VERSION ""

NS_ :

BS_:

BU_: SEND RECV

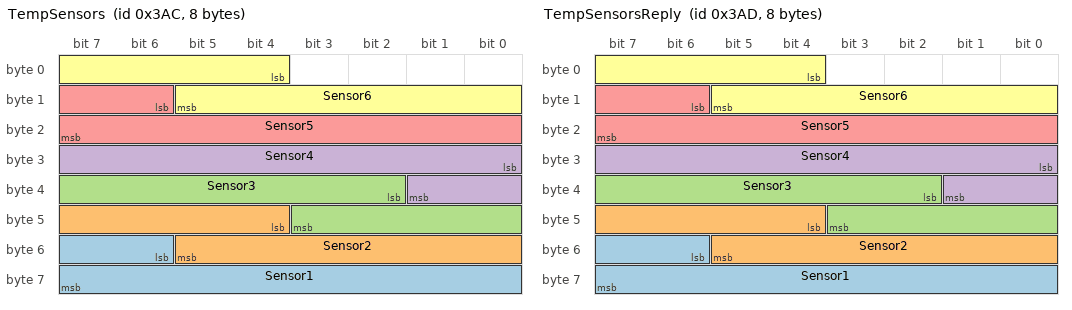
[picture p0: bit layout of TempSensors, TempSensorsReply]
BO_ 940 TempSensors: 8 SEND
    SG_ Sensor1 : 54|10@1- (0.2,0) [0|0] "degC" RECV
    SG_ Sensor2 : 44|10@1- (0.2,0) [0|0] "degC" RECV
    SG_ Sensor3 : 34|10@1- (0.2,0) [0|0] "degC" RECV
    SG_ Sensor4 : 24|10@1- (0.2,0) [0|0] "degC" RECV
    SG_ Sensor5 : 14|10@1- (0.2,0) [0|0] "degC" RECV
    SG_ Sensor6 : 4|10@1- (0.2,0) [0|0] "degC" RECV

BO_ 941 TempSensorsReply: 8 RECV
    SG_ Sensor1 : 54|10@1- (0.2,0) [0|0] "degC" SEND
    SG_ Sensor2 : 44|10@1- (0.2,0) [0|0] "degC" SEND
    SG_ Sensor3 : 34|10@1- (0.2,0) [0|0] "degC" SEND
    SG_ Sensor4 : 24|10@1- (0.2,0) [0|0] "degC" SEND
    SG_ Sensor5 : 14|10@1- (0.2,0) [0|0] "degC" SEND
    SG_ Sensor6 : 4|10@1- (0.2,0) [0|0] "degC" SEND
